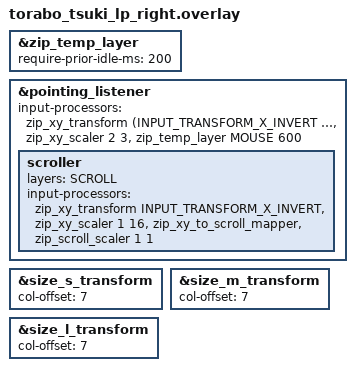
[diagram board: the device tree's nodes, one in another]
#include "torabo_tsuki_lp.dtsi"
#include <input/processors.dtsi>
#include <dt-bindings/zmk/input_transform.h>

#define MOUSE 4
#define SCROLL 5

&zip_temp_layer {
    require-prior-idle-ms = <200>;
};

&pointing_listener {
    input-processors = 
        <&zip_xy_transform (INPUT_TRANSFORM_X_INVERT | INPUT_TRANSFORM_Y_INVERT)>,
        <&zip_xy_scaler 2 3>,
        <&zip_temp_layer MOUSE 600>;
    scroller {
        layers = <SCROLL>;
        input-processors = 
            <&zip_xy_transform INPUT_TRANSFORM_X_INVERT>,
            <&zip_xy_scaler 1 16>,
            <&zip_xy_to_scroll_mapper>,
            <&zip_scroll_scaler 1 1>;
    };
};

&size_s_transform {
    col-offset = <7>;
};

&size_m_transform {
    col-offset = <7>;
};

&size_l_transform {
    col-offset = <7>;
};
